# RT58X register map
Series: ARMv8-M Mainline; File version: 1.0
CPU: CM3 r0p0, little endian, MPU, no FPU, VTOR, 3 interrupt priority bits
Registers are 32-bit, read-write, reset 0x0 unless marked. A register's access mark holds for its fields unless they carry their own. Offsets are from the block's base; [hi:lo] are bit positions; {n}, {i} and the like mark numbered series.

## SYS_CTRL — SYS_CTRL Register block
Base 0x40800000
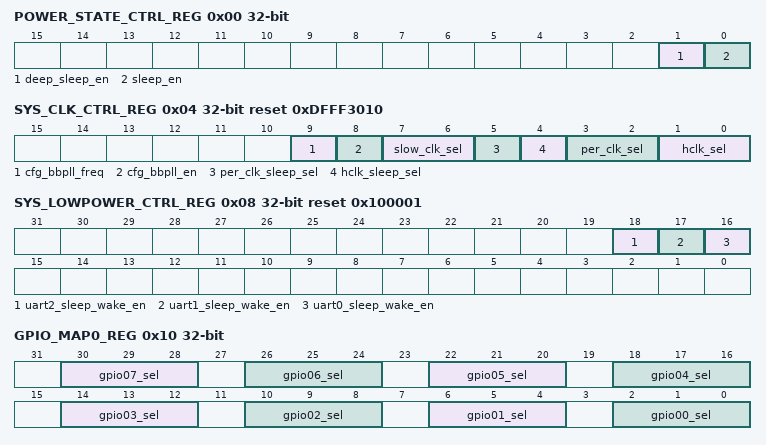
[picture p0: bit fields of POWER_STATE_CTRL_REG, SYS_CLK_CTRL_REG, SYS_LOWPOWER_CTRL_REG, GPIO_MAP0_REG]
0x00 POWER_STATE_CTRL_REG wo — power state ctrl
  [1] deep_sleep_en — Write 1 to enter DeepSleep.
    0=B_1 (Write 1 to enter DeepSleep.)
  [0] sleep_en — Write 1 to enter Sleep.
    0=B_0 (Write 1 to enter Sleep.)
0x04 SYS_CLK_CTRL_REG reset 0xDFFF3010 — sys clk ctrl
  [9] cfg_bbpll_freq — Baseband PLL frequency 0: 48MHz 1: 64MHz
    0=B_9_ITEM0 (48MHz); 1=B_9_ITEM1 (64MHz)
  [8] cfg_bbpll_en — Baseband PLL enable 0: disabl 1: enable
    0=B_8_ITEM0 (disabl); 1=B_8_ITEM1 (enable)
  [7:6] slow_clk_sel — Slow clock selection 0: From internal RCO 1: From GPIO 2: From 32M / 1000 3: From XO 32K
    0=B_6_to_7_ITEM0 (From internal RCO); 1=B_6_to_7_ITEM1 (From GPIO); 2=B_6_to_7_ITEM2 (From 32M / 1000); 3=B_6_to_7_ITEM3 (From XO 32K)
  [5] per_clk_sleep_sel — Peripheral clock selection in Sleep 0: Peripheral clock is disabled in Sleep 1: Peripheral clock is forced to 32K in Sleep.
    0=B_5_ITEM0 (Peripheral clock is disabled in Sleep); 1=B_5_ITEM1 (Peripheral clock is forced to 32K in Sleep.)
  [4] hclk_sleep_sel — HCLK sleep selection in Sleep 0: HCLK is disabled in Sleep 1: HCLK is forced to 32K in Sleep.
    0=B_4_ITEM0 (HCLK is disabled in Sleep); 1=B_4_ITEM1 (HCLK is forced to 32K in Sleep.)
  [3:2] per_clk_sel — Peripheral clock selection 0: XTAL (32M) 1: XTAL / 2 (16M) 2: Slow clock 3: Slow clock
    0=B_2_to_3_ITEM0 (XTAL (32M)); 1=B_2_to_3_ITEM1 (XTAL / 2 (16M)); 2=B_2_to_3_ITEM2 (Slow clock); 3=B_2_to_3_ITEM3 (Slow clock)
  [1:0] hclk_sel — HCLK selection 0: XTAL (32M) 1: XTAL / 2 (16M) 2: Slow clock 3: PLL clock
    0=B_0_to_1_ITEM0 (XTAL (32M)); 1=B_0_to_1_ITEM1 (XTAL / 2 (16M)); 2=B_0_to_1_ITEM2 (Slow clock); 3=B_0_to_1_ITEM3 (PLL clock)
0x08 SYS_LOWPOWER_CTRL_REG reset 0x100001 — sys lowpower ctrl
  [18] uart2_sleep_wake_en — UART2 sleep wake enable 0: disable 1: enable
    0=B_18_ITEM0 (disable); 1=B_18_ITEM1 (enable)
  [17] uart1_sleep_wake_en — UART1 sleep wake enable 0: disable 1: enable
    0=B_17_ITEM0 (disable); 1=B_17_ITEM1 (enable)
  [16] uart0_sleep_wake_en — UART0 sleep wake enable 0: disable 1: enable
    0=B_16_ITEM0 (disable); 1=B_16_ITEM1 (enable)
0x10 GPIO_MAP0_REG — gpio map0
  [30:28] gpio07_sel — 0: GPIO7 1: SPI0_CSN0 2: N/A 3: X51_TDI 4: N/A 5: EXT32K 6: UART2_RX 7: DBG_OUT[7]
    0=B_28_to_30_ITEM0 (GPIO7); 1=B_28_to_30_ITEM1 (SPI0_CSN0); 2=B_28_to_30_ITEM2 (N/A); 3=B_28_to_30_ITEM3 (X51_TDI); 4=B_28_to_30_ITEM4 (N/A); 5=B_28_to_30_ITEM5 (EXT32K); 6=B_28_to_30_ITEM6 (UART2_RX); 7=B_28_to_30_ITEM7 (DBG_OUT[7])
  [26:24] gpio06_sel — 0: GPIO6 1: SPI0_SCLK 2: N/A 3: X51_TCK 4: N/A 5: EXT32K 6: UART2_TX 7: DBG_OUT[6]
    0=B_24_to_26_ITEM0 (GPIO6); 1=B_24_to_26_ITEM1 (SPI0_SCLK); 2=B_24_to_26_ITEM2 (N/A); 3=B_24_to_26_ITEM3 (X51_TCK); 4=B_24_to_26_ITEM4 (N/A); 5=B_24_to_26_ITEM5 (EXT32K); 6=B_24_to_26_ITEM6 (UART2_TX); 7=B_24_to_26_ITEM7 (DBG_OUT[6])
  [22:20] gpio05_sel — 0: GPIO5 1: SPI0_SDATA3 2: N/A 3: X51_TMS 4: I2S0_MCLK 5: EXT32K 6: UART1_RX 7: DBG_OUT[5]
    0=B_20_to_22_ITEM0 (GPIO5); 1=B_20_to_22_ITEM1 (SPI0_SDATA3); 2=B_20_to_22_ITEM2 (N/A); 3=B_20_to_22_ITEM3 (X51_TMS); 4=B_20_to_22_ITEM4 (I2S0_MCLK); 5=B_20_to_22_ITEM5 (EXT32K); 6=B_20_to_22_ITEM6 (UART1_RX); 7=B_20_to_22_ITEM7 (DBG_OUT[5])
  [18:16] gpio04_sel — 0: GPIO4 1: SPI0_SDATA2 2: N/A 3: N/A 4: I2S0_MCLK 5: EXT32K 6: UART1_TX 7: DBG_OUT[4]
    0=B_16_to_18_ITEM0 (GPIO4); 1=B_16_to_18_ITEM1 (SPI0_SDATA2); 2=B_16_to_18_ITEM2 (N/A); 3=B_16_to_18_ITEM3 (N/A); 4=B_16_to_18_ITEM4 (I2S0_MCLK); 5=B_16_to_18_ITEM5 (EXT32K); 6=B_16_to_18_ITEM6 (UART1_TX); 7=B_16_to_18_ITEM7 (DBG_OUT[4])
  [14:12] gpio03_sel — 0: GPIO3 1: N/A 2: SPI0_CSN1 3: SPI0_CSN2 4: I2S0_SDI 5: EXT32K 6: SPI0_CSN3 7: DBG_OUT[3]
    0=B_12_to_14_ITEM0 (GPIO3); 1=B_12_to_14_ITEM1 (N/A); 2=B_12_to_14_ITEM2 (SPI0_CSN1); 3=B_12_to_14_ITEM3 (SPI0_CSN2); 4=B_12_to_14_ITEM4 (I2S0_SDI); 5=B_12_to_14_ITEM5 (EXT32K); 6=B_12_to_14_ITEM6 (SPI0_CSN3); 7=B_12_to_14_ITEM7 (DBG_OUT[3])
  [10:8] gpio02_sel — 0: GPIO2 1: N/A 2: SPI0_CSN1 3: SPI0_CSN2 4: I2S0_SDO 5: EXT32K 6: SPI0_CSN3 7: DBG_OUT[2]
    0=B_8_to_10_ITEM0 (GPIO2); 1=B_8_to_10_ITEM1 (N/A); 2=B_8_to_10_ITEM2 (SPI0_CSN1); 3=B_8_to_10_ITEM3 (SPI0_CSN2); 4=B_8_to_10_ITEM4 (I2S0_SDO); 5=B_8_to_10_ITEM5 (EXT32K); 6=B_8_to_10_ITEM6 (SPI0_CSN3); 7=B_8_to_10_ITEM7 (DBG_OUT[2])
  [6:4] gpio01_sel — 0: GPIO1 1: N/A 2: SPI0_CSN1 3: SPI0_CSN2 4: I2S0_WCK 5: EXT32K 6: SPI0_CSN3 7: DBG_OUT[1]
    0=B_4_to_6_ITEM0 (GPIO1); 1=B_4_to_6_ITEM1 (N/A); 2=B_4_to_6_ITEM2 (SPI0_CSN1); 3=B_4_to_6_ITEM3 (SPI0_CSN2); 4=B_4_to_6_ITEM4 (I2S0_WCK); 5=B_4_to_6_ITEM5 (EXT32K); 6=B_4_to_6_ITEM6 (SPI0_CSN3); 7=B_4_to_6_ITEM7 (DBG_OUT[1])
  [2:0] gpio00_sel — 0: GPIO0 1: N/A 2: SPI0_CSN1 3: SPI0_CSN2 4: I2S0_BCK 5: EXT32K 6: SPI0_CSN3 7: DBG_OUT[0]
    0=B_0_to_2_ITEM0 (GPIO0); 1=B_0_to_2_ITEM1 (N/A); 2=B_0_to_2_ITEM2 (SPI0_CSN1); 3=B_0_to_2_ITEM3 (SPI0_CSN2); 4=B_0_to_2_ITEM4 (I2S0_BCK); 5=B_0_to_2_ITEM5 (EXT32K); 6=B_0_to_2_ITEM6 (SPI0_CSN3); 7=B_0_to_2_ITEM7 (DBG_OUT[0])
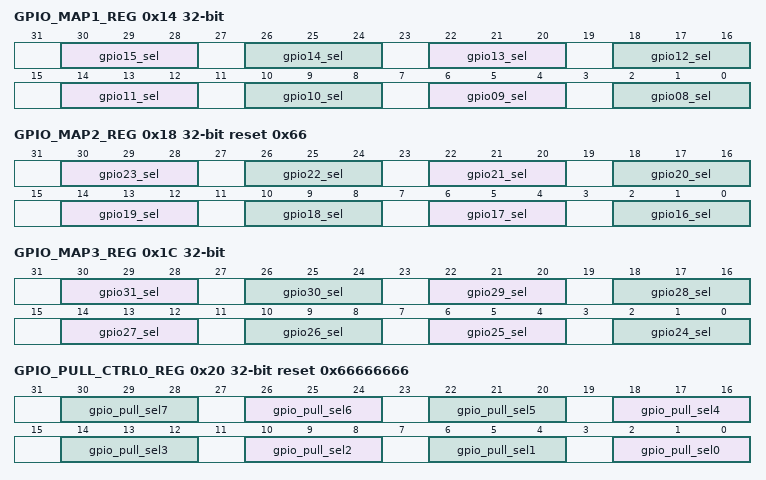
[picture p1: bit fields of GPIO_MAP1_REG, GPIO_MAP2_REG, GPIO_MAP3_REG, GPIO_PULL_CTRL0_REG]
0x14 GPIO_MAP1_REG — gpio map1
  [30:28] gpio15_sel — 0: GPIO15 1: SPI0_SDATA3 2: N/A 3: N/A 4: PWM3 5: SPI1_SDATA3 6: UART1_CTSN 7: DBG_OUT[11]
    0=B_28_to_30_ITEM0 (GPIO15); 1=B_28_to_30_ITEM1 (SPI0_SDATA3); 2=B_28_to_30_ITEM2 (N/A); 3=B_28_to_30_ITEM3 (N/A); 4=B_28_to_30_ITEM4 (PWM3); 5=B_28_to_30_ITEM5 (SPI1_SDATA3); 6=B_28_to_30_ITEM6 (UART1_CTSN); 7=B_28_to_30_ITEM7 (DBG_OUT[11])
  [26:24] gpio14_sel — 0: GPIO14 1: SPI0_SDATA2 2: N/A 3: N/A 4: PWM2 5: SPI1_SDATA2 6: UART1_RTSN 7: DBG_OUT[10]
    0=B_24_to_26_ITEM0 (GPIO14); 1=B_24_to_26_ITEM1 (SPI0_SDATA2); 2=B_24_to_26_ITEM2 (N/A); 3=B_24_to_26_ITEM3 (N/A); 4=B_24_to_26_ITEM4 (PWM2); 5=B_24_to_26_ITEM5 (SPI1_SDATA2); 6=B_24_to_26_ITEM6 (UART1_RTSN); 7=B_24_to_26_ITEM7 (DBG_OUT[10])
  [22:20] gpio13_sel — 0: GPIO13 1: PWM0 2: PWM1 3: PWM2 4: I2S0_SDI 5: PWM3 6: UART2_RX 7: PWM4
    0=B_20_to_22_ITEM0 (GPIO13); 1=B_20_to_22_ITEM1 (PWM0); 2=B_20_to_22_ITEM2 (PWM1); 3=B_20_to_22_ITEM3 (PWM2); 4=B_20_to_22_ITEM4 (I2S0_SDI); 5=B_20_to_22_ITEM5 (PWM3); 6=B_20_to_22_ITEM6 (UART2_RX); 7=B_20_to_22_ITEM7 (PWM4)
  [18:16] gpio12_sel — 0: GPIO12 1: PWM0 2: PWM1 3: PWM2 4: I2S0_SDO 5: PWM3 6: UART2_TX 7: PWM4
    0=B_16_to_18_ITEM0 (GPIO12); 1=B_16_to_18_ITEM1 (PWM0); 2=B_16_to_18_ITEM2 (PWM1); 3=B_16_to_18_ITEM3 (PWM2); 4=B_16_to_18_ITEM4 (I2S0_SDO); 5=B_16_to_18_ITEM5 (PWM3); 6=B_16_to_18_ITEM6 (UART2_TX); 7=B_16_to_18_ITEM7 (PWM4)
  [14:12] gpio11_sel — 0: GPIO11 1: PWM0 2: PWM1 3: PWM2 4: I2S0_WCK 5: PWM3 6: UART1_RX 7: PWM4
    0=B_12_to_14_ITEM0 (GPIO11); 1=B_12_to_14_ITEM1 (PWM0); 2=B_12_to_14_ITEM2 (PWM1); 3=B_12_to_14_ITEM3 (PWM2); 4=B_12_to_14_ITEM4 (I2S0_WCK); 5=B_12_to_14_ITEM5 (PWM3); 6=B_12_to_14_ITEM6 (UART1_RX); 7=B_12_to_14_ITEM7 (PWM4)
  [10:8] gpio10_sel — 0: GPIO10 1: PWM0 2: PWM1 3: PWM2 4: I2S0_BCK 5: PWM3 6: UART1_TX 7: PWM4
    0=B_8_to_10_ITEM0 (GPIO10); 1=B_8_to_10_ITEM1 (PWM0); 2=B_8_to_10_ITEM2 (PWM1); 3=B_8_to_10_ITEM3 (PWM2); 4=B_8_to_10_ITEM4 (I2S0_BCK); 5=B_8_to_10_ITEM5 (PWM3); 6=B_8_to_10_ITEM6 (UART1_TX); 7=B_8_to_10_ITEM7 (PWM4)
  [6:4] gpio09_sel — 0: GPIO9 1: SPI0_SDATA1 2: N/A 3: X51_RTCK 4: PWM1 5: EXT32K 6: N/A 7: DBG_OUT[9]
    0=B_4_to_6_ITEM0 (GPIO9); 1=B_4_to_6_ITEM1 (SPI0_SDATA1); 2=B_4_to_6_ITEM2 (N/A); 3=B_4_to_6_ITEM3 (X51_RTCK); 4=B_4_to_6_ITEM4 (PWM1); 5=B_4_to_6_ITEM5 (EXT32K); 6=B_4_to_6_ITEM6 (N/A); 7=B_4_to_6_ITEM7 (DBG_OUT[9])
  [2:0] gpio08_sel — 0: GPIO8 1: SPI0_SDATA0 2: N/A 3: X51_TDO 4: PWM0 5: N/A 6: EXT32K 7: DBG_OUT[8]
    0=B_0_to_2_ITEM0 (GPIO8); 1=B_0_to_2_ITEM1 (SPI0_SDATA0); 2=B_0_to_2_ITEM2 (N/A); 3=B_0_to_2_ITEM3 (X51_TDO); 4=B_0_to_2_ITEM4 (PWM0); 5=B_0_to_2_ITEM5 (N/A); 6=B_0_to_2_ITEM6 (EXT32K); 7=B_0_to_2_ITEM7 (DBG_OUT[8])
0x18 GPIO_MAP2_REG reset 0x66 — gpio map2
  [30:28] gpio23_sel — 0: GPIO23 1: PWM0 2: PWM1 3: PWM2 4: I2C_SDA 5: PWM3 6: N/A 7: PWM4
    0=B_28_to_30_ITEM0 (GPIO23); 1=B_28_to_30_ITEM1 (PWM0); 2=B_28_to_30_ITEM2 (PWM1); 3=B_28_to_30_ITEM3 (PWM2); 4=B_28_to_30_ITEM4 (I2C_SDA); 5=B_28_to_30_ITEM5 (PWM3); 6=B_28_to_30_ITEM6 (N/A); 7=B_28_to_30_ITEM7 (PWM4)
  [26:24] gpio22_sel — 0: GPIO22 1: PWM0 2: PWM1 3: PWM2 4: I2C_SCL 5: PWM3 6: N/A 7: PWM4
    0=B_24_to_26_ITEM0 (GPIO22); 1=B_24_to_26_ITEM1 (PWM0); 2=B_24_to_26_ITEM2 (PWM1); 3=B_24_to_26_ITEM3 (PWM2); 4=B_24_to_26_ITEM4 (I2C_SCL); 5=B_24_to_26_ITEM5 (PWM3); 6=B_24_to_26_ITEM6 (N/A); 7=B_24_to_26_ITEM7 (PWM4)
  [22:20] gpio21_sel — 0: GPIO21 1: PWM0 2: PWM1 3: PWM2 4: I2C_SDA 5: PWM3 6: UART1_CTSN 7: PWM4
    0=B_20_to_22_ITEM0 (GPIO21); 1=B_20_to_22_ITEM1 (PWM0); 2=B_20_to_22_ITEM2 (PWM1); 3=B_20_to_22_ITEM3 (PWM2); 4=B_20_to_22_ITEM4 (I2C_SDA); 5=B_20_to_22_ITEM5 (PWM3); 6=B_20_to_22_ITEM6 (UART1_CTSN); 7=B_20_to_22_ITEM7 (PWM4)
  [18:16] gpio20_sel — 0: GPIO20 1: PWM0 2: PWM1 3: PWM2 4: I2C_SCL 5: PWM3 6: UART1_RTSN 7: PWM4
    0=B_16_to_18_ITEM0 (GPIO20); 1=B_16_to_18_ITEM1 (PWM0); 2=B_16_to_18_ITEM2 (PWM1); 3=B_16_to_18_ITEM3 (PWM2); 4=B_16_to_18_ITEM4 (I2C_SCL); 5=B_16_to_18_ITEM5 (PWM3); 6=B_16_to_18_ITEM6 (UART1_RTSN); 7=B_16_to_18_ITEM7 (PWM4)
  [14:12] gpio19_sel — 0: GPIO19 1: PWM0 2: PWM1 3: PWM2 4: I2C_SDA 5: PWM3 6: UART1_CTSN 7: PWM4
    0=B_12_to_14_ITEM0 (GPIO19); 1=B_12_to_14_ITEM1 (PWM0); 2=B_12_to_14_ITEM2 (PWM1); 3=B_12_to_14_ITEM3 (PWM2); 4=B_12_to_14_ITEM4 (I2C_SDA); 5=B_12_to_14_ITEM5 (PWM3); 6=B_12_to_14_ITEM6 (UART1_CTSN); 7=B_12_to_14_ITEM7 (PWM4)
  [10:8] gpio18_sel — 0: GPIO18 1: PWM0 2: PWM1 3: PWM2 4: I2C_SCL 5: PWM3 6: UART1_RTSN 7: PWM4
    0=B_8_to_10_ITEM0 (GPIO18); 1=B_8_to_10_ITEM1 (PWM0); 2=B_8_to_10_ITEM2 (PWM1); 3=B_8_to_10_ITEM3 (PWM2); 4=B_8_to_10_ITEM4 (I2C_SCL); 5=B_8_to_10_ITEM5 (PWM3); 6=B_8_to_10_ITEM6 (UART1_RTSN); 7=B_8_to_10_ITEM7 (PWM4)
  [6:4] gpio17_sel — 0: GPIO17 1: N/A 2: N/A 3: N/A 4: N/A 5: N/A 6: UART0_TX 7: N/A
    0=B_4_to_6_ITEM0 (GPIO17); {v}=B_4_to_6_ITEM{v} (N/A) (v=1..5); 6=B_4_to_6_ITEM6 (UART0_TX); 7=B_4_to_6_ITEM7 (N/A)
  [2:0] gpio16_sel — 0: GPIO16 1: N/A 2: N/A 3: N/A 4: N/A 5: N/A 6: UART0_RX 7: N/A
    0=B_0_to_2_ITEM0 (GPIO16); {v}=B_0_to_2_ITEM{v} (N/A) (v=1..5); 6=B_0_to_2_ITEM6 (UART0_RX); 7=B_0_to_2_ITEM7 (N/A)
0x1C GPIO_MAP3_REG — gpio map3
  [30:28] gpio31_sel — 0: GPIO31 1: SPI0_SDATA1 2: N/A 3: N/A 4: N/A 5: SPI1_SDATA1 6: UART2_RX 7: DBG_OUT[15]
    0=B_28_to_30_ITEM0 (GPIO31); 1=B_28_to_30_ITEM1 (SPI0_SDATA1); 2=B_28_to_30_ITEM2 (N/A); 3=B_28_to_30_ITEM3 (N/A); 4=B_28_to_30_ITEM4 (N/A); 5=B_28_to_30_ITEM5 (SPI1_SDATA1); 6=B_28_to_30_ITEM6 (UART2_RX); 7=B_28_to_30_ITEM7 (DBG_OUT[15])
  [26:24] gpio30_sel — 0: GPIO30 1: SPI0_SDATA0 2: N/A 3: N/A 4: N/A 5: SPI1_SDATA0 6: UART2_TX 7: DBG_OUT[13]
    0=B_24_to_26_ITEM0 (GPIO30); 1=B_24_to_26_ITEM1 (SPI0_SDATA0); 2=B_24_to_26_ITEM2 (N/A); 3=B_24_to_26_ITEM3 (N/A); 4=B_24_to_26_ITEM4 (N/A); 5=B_24_to_26_ITEM5 (SPI1_SDATA0); 6=B_24_to_26_ITEM6 (UART2_TX); 7=B_24_to_26_ITEM7 (DBG_OUT[13])
  [22:20] gpio29_sel — 0: GPIO29 1: SPI0_CSN0 2: N/A 3: N/A 4: N/A 5: SPI1_CSN 6: UART1_RX 7: DBG_OUT[13]
    0=B_20_to_22_ITEM0 (GPIO29); 1=B_20_to_22_ITEM1 (SPI0_CSN0); 2=B_20_to_22_ITEM2 (N/A); 3=B_20_to_22_ITEM3 (N/A); 4=B_20_to_22_ITEM4 (N/A); 5=B_20_to_22_ITEM5 (SPI1_CSN); 6=B_20_to_22_ITEM6 (UART1_RX); 7=B_20_to_22_ITEM7 (DBG_OUT[13])
  [18:16] gpio28_sel — 0: GPIO28 1: SPI0_SCLK 2: N/A 3: N/A 4: N/A 5: SPI1_SCLK 6: UART1_TX 7: DBG_OUT[12]
    0=B_16_to_18_ITEM0 (GPIO28); 1=B_16_to_18_ITEM1 (SPI0_SCLK); 2=B_16_to_18_ITEM2 (N/A); 3=B_16_to_18_ITEM3 (N/A); 4=B_16_to_18_ITEM4 (N/A); 5=B_16_to_18_ITEM5 (SPI1_SCLK); 6=B_16_to_18_ITEM6 (UART1_TX); 7=B_16_to_18_ITEM7 (DBG_OUT[12])
  [14:12] gpio27_sel — 0: GPIO27 1: SPI0_SDATA1 2: SPI0_CSN1 3: SPI0_CSN2 4: N/A 5: SPI1_SDATA1 6: SPI0_CSN3 7: N/A
    0=B_12_to_14_ITEM0 (GPIO27); 1=B_12_to_14_ITEM1 (SPI0_SDATA1); 2=B_12_to_14_ITEM2 (SPI0_CSN1); 3=B_12_to_14_ITEM3 (SPI0_CSN2); 4=B_12_to_14_ITEM4 (N/A); 5=B_12_to_14_ITEM5 (SPI1_SDATA1); 6=B_12_to_14_ITEM6 (SPI0_CSN3); 7=B_12_to_14_ITEM7 (N/A)
  [10:8] gpio26_sel — 0: GPIO26 1: SPI0_SDATA0 2: SPI0_CSN1 3: SPI0_CSN2 4: N/A 5: SPI1_SDATA0 6: SPI0_CSN3 7: N/A
    0=B_8_to_10_ITEM0 (GPIO26); 1=B_8_to_10_ITEM1 (SPI0_SDATA0); 2=B_8_to_10_ITEM2 (SPI0_CSN1); 3=B_8_to_10_ITEM3 (SPI0_CSN2); 4=B_8_to_10_ITEM4 (N/A); 5=B_8_to_10_ITEM5 (SPI1_SDATA0); 6=B_8_to_10_ITEM6 (SPI0_CSN3); 7=B_8_to_10_ITEM7 (N/A)
  [6:4] gpio25_sel — 0: GPIO25 1: SPI0_CSN0 2: SPI0_CSN1 3: SPI0_CSN2 4: N/A 5: SPI1_CSN 6: SPI0_CSN3 7: N/A
    0=B_4_to_6_ITEM0 (GPIO25); 1=B_4_to_6_ITEM1 (SPI0_CSN0); 2=B_4_to_6_ITEM2 (SPI0_CSN1); 3=B_4_to_6_ITEM3 (SPI0_CSN2); 4=B_4_to_6_ITEM4 (N/A); 5=B_4_to_6_ITEM5 (SPI1_CSN); 6=B_4_to_6_ITEM6 (SPI0_CSN3); 7=B_4_to_6_ITEM7 (N/A)
  [2:0] gpio24_sel — 0: GPIO24 1: SPI0_SCLK 2: SPI0_CSN1 3: SPI0_CSN2 4: N/A 5: SPI1_SCLK 6: SPI0_CSN3 7: N/A
    0=B_0_to_2_ITEM0 (GPIO24); 1=B_0_to_2_ITEM1 (SPI0_SCLK); 2=B_0_to_2_ITEM2 (SPI0_CSN1); 3=B_0_to_2_ITEM3 (SPI0_CSN2); 4=B_0_to_2_ITEM4 (N/A); 5=B_0_to_2_ITEM5 (SPI1_SCLK); 6=B_0_to_2_ITEM6 (SPI0_CSN3); 7=B_0_to_2_ITEM7 (N/A)
0x20 GPIO_PULL_CTRL0_REG reset 0x66666666 — gpio pull ctrl0
  [4n+2:4n] gpio_pull_sel{n} (n=0..7) — GPIO{n} pull select 0: no pull 1: 10K pull down 2: 100K pull down 3: 1M pull down 4: no pull 5: 10k pull up 6: 100K pull up 7: 1M pull up
    0=B_{4n}_to_{4n+2}_ITEM0 (no pull); 1=B_{4n}_to_{4n+2}_ITEM1 (10K pull down); 2=B_{4n}_to_{4n+2}_ITEM2 (100K pull down); 3=B_{4n}_to_{4n+2}_ITEM3 (1M pull down); 4=B_{4n}_to_{4n+2}_ITEM4 (no pull); 5=B_{4n}_to_{4n+2}_ITEM5 (10k pull up); 6=B_{4n}_to_{4n+2}_ITEM6 (100K pull up); 7=B_{4n}_to_{4n+2}_ITEM7 (1M pull up)
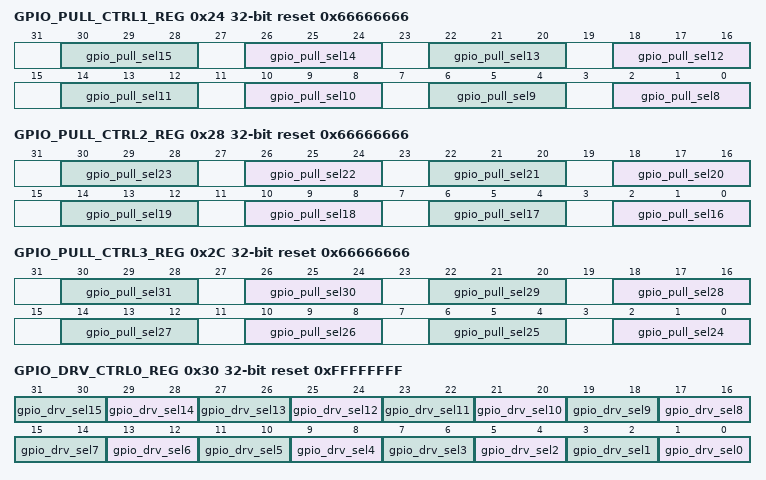
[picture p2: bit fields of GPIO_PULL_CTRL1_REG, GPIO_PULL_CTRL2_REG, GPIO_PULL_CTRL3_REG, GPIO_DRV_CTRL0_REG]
0x24 GPIO_PULL_CTRL1_REG reset 0x66666666 — gpio pull ctrl1
  [4n-30:4n-32] gpio_pull_sel{n} (n=8..15) — GPIO{n} pull select 0: no pull 1: 10K pull down 2: 100K pull down 3: 1M pull down 4: no pull 5: 10k pull up 6: 100K pull up 7: 1M pull up
    0=B_{4n-32}_to_{4n-30}_ITEM0 (no pull); 1=B_{4n-32}_to_{4n-30}_ITEM1 (10K pull down); 2=B_{4n-32}_to_{4n-30}_ITEM2 (100K pull down); 3=B_{4n-32}_to_{4n-30}_ITEM3 (1M pull down); 4=B_{4n-32}_to_{4n-30}_ITEM4 (no pull); 5=B_{4n-32}_to_{4n-30}_ITEM5 (10k pull up); 6=B_{4n-32}_to_{4n-30}_ITEM6 (100K pull up); 7=B_{4n-32}_to_{4n-30}_ITEM7 (1M pull up)
0x28 GPIO_PULL_CTRL2_REG reset 0x66666666 — gpio pull ctrl2
  [4n-62:4n-64] gpio_pull_sel{n} (n=16..23) — GPIO{n} pull select 0: no pull 1: 10K pull down 2: 100K pull down 3: 1M pull down 4: no pull 5: 10k pull up 6: 100K pull up 7: 1M pull up
    0=B_{4n-64}_to_{4n-62}_ITEM0 (no pull); 1=B_{4n-64}_to_{4n-62}_ITEM1 (10K pull down); 2=B_{4n-64}_to_{4n-62}_ITEM2 (100K pull down); 3=B_{4n-64}_to_{4n-62}_ITEM3 (1M pull down); 4=B_{4n-64}_to_{4n-62}_ITEM4 (no pull); 5=B_{4n-64}_to_{4n-62}_ITEM5 (10k pull up); 6=B_{4n-64}_to_{4n-62}_ITEM6 (100K pull up); 7=B_{4n-64}_to_{4n-62}_ITEM7 (1M pull up)
0x2C GPIO_PULL_CTRL3_REG reset 0x66666666 — gpio pull ctrl3
  [4n-94:4n-96] gpio_pull_sel{n} (n=24..31) — GPIO{n} pull select 0: no pull 1: 10K pull down 2: 100K pull down 3: 1M pull down 4: no pull 5: 10k pull up 6: 100K pull up 7: 1M pull up
    0=B_{4n-96}_to_{4n-94}_ITEM0 (no pull); 1=B_{4n-96}_to_{4n-94}_ITEM1 (10K pull down); 2=B_{4n-96}_to_{4n-94}_ITEM2 (100K pull down); 3=B_{4n-96}_to_{4n-94}_ITEM3 (1M pull down); 4=B_{4n-96}_to_{4n-94}_ITEM4 (no pull); 5=B_{4n-96}_to_{4n-94}_ITEM5 (10k pull up); 6=B_{4n-96}_to_{4n-94}_ITEM6 (100K pull up); 7=B_{4n-96}_to_{4n-94}_ITEM7 (1M pull up)
0x30 GPIO_DRV_CTRL0_REG reset 0xFFFFFFFF — gpio drv ctrl0
  [2n+1:2n] gpio_drv_sel{n} (n=0..15) — GPIO{n} driving selection 0: driving strength 0 (weakest) 1: driving strength 1 2: driving strength 2 3: driving strength 3 (strongest)
    0=B_{2n}_to_{2n+1}_ITEM0 (driving strength 0 (weakest)); 1=B_{2n}_to_{2n+1}_ITEM1 (driving strength 1); 2=B_{2n}_to_{2n+1}_ITEM2 (driving strength 2); 3=B_{2n}_to_{2n+1}_ITEM3 (driving strength 3 (strongest))
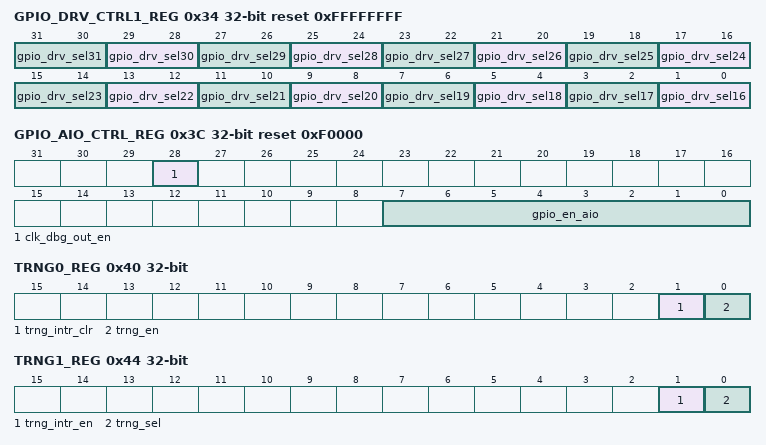
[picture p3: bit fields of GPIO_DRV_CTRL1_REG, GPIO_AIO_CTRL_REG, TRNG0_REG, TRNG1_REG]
0x34 GPIO_DRV_CTRL1_REG reset 0xFFFFFFFF — gpio drv ctrl1
  [2n-31:2n-32] gpio_drv_sel{n} (n=16..31) — GPIO{n} driving selection 0: driving strength 0 (weakest) 1: driving strength 1 2: driving strength 2 3: driving strength 3 (strongest)
    0=B_{2n-32}_to_{2n-31}_ITEM0 (driving strength 0 (weakest)); 1=B_{2n-32}_to_{2n-31}_ITEM1 (driving strength 1); 2=B_{2n-32}_to_{2n-31}_ITEM2 (driving strength 2); 3=B_{2n-32}_to_{2n-31}_ITEM3 (driving strength 3 (strongest))
0x38 GPIO_OD_CTRL_REG — GPIOx open-drain enable 0: disabled 1: enabled
0x3C GPIO_AIO_CTRL_REG reset 0xF0000 — gpio aio ctrl
  [28] clk_dbg_out_en
    0=B_28 (clk dbg out en)
  [7:0] gpio_en_aio — AIOx enable 0: disabled 1: enabled
    0=B_0_to_7 (AIOx enable 0: disabled 1: enabled)
0x40 TRNG0_REG wo — trng0
  [1] trng_intr_clr — Write 1 to clear TRNG interrupt status.
    0=B_1 (Write 1 to clear TRNG interrupt status.)
  [0] trng_en — Write 1 to trigger TRNG
    0=B_0 (Write 1 to trigger TRNG)
0x44 TRNG1_REG — trng1
  [1] trng_intr_en — TRNG interrupt enable 0: disabled 1: enabled
    0=B_1_ITEM0 (disabled); 1=B_1_ITEM1 (enabled)
  [0] trng_sel — TRNG corrector method 0: von Neumann corrector 1: XOR corrector
    0=B_0_ITEM0 (von Neumann corrector); 1=B_0_ITEM1 (XOR corrector)
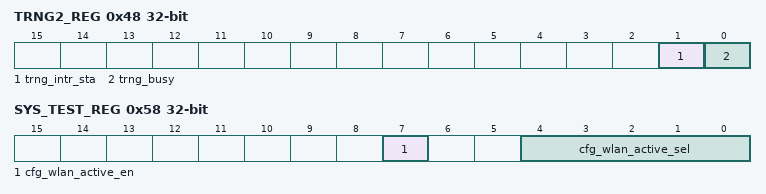
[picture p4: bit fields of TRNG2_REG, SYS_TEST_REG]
0x48 TRNG2_REG ro — trng2
  [1] trng_intr_sta — TRNG interrupt status 0: no interrupt pending 1: interrupt pending
    0=B_1_ITEM0 (no interrupt pending); 1=B_1_ITEM1 (interrupt pending)
  [0] trng_busy — TRNG busy 0: not busy 1: busy
    0=B_0_ITEM0 (not busy); 1=B_0_ITEM1 (busy)
0x4C TRNG3_REG ro — TRNG output
0x58 SYS_TEST_REG — sys test
  [7] cfg_wlan_active_en — Enable GPIOxx input for wlan_active for RT569 PTA function.
    0=B_7 (Enable GPIOxx input for wlan_active for RT569 PTA function.)
  [4:0] cfg_wlan_active_sel — Select the related GPIOxx input for wlan_active for RT569 PTA function.
    0=B_0_to_4 (Select the related GPIOxx input for wlan_active for RT569 PTA function.)
{0x60+4i} SYS_SCRATCHPAD_{i}_REG (i=0..5) — Scratch PAD{i}. This value is kept after waking up from Deep Sleep.
0x78 SYS_SCRATCHPAD_6_REG — Scratch PAD6. Reserved for System Use. [0] : Enable resetting CM3 peripherals when WatchDog reset is triggered. [1] : Enable resetting ApbGPIO and Remap when WatchDog reset is triggered. [2] : Enable resetting RT569 when WatchDog reset is triggered. Others: N/A
0x7C SYS_SCRATCHPAD_7_REG — Scratch PAD7. This value is kept after waking up from Deep Sleep. [8] : Disable ICE. Once this bit is set to 1, it can't be set to 0 again except power-on reset or external reset. 0: Enable ICE (default) 1: Disable ICE [15:9] Don't USE due to no function. Others : They can be written normally.
0x80 DEEPSLEEP_WAKEUP_REG — Set the corresponding bits to enable the wakeup of GPIOx in Deep Sleep
0x84 DEEPSLEEP_INV_REG — Set the corresponding bits to invert the GPIOx for wakeup in Deep Sleep
0x90 RT570_CHIP_INFO_REG ro reset 0x7702F — rt570 chip info
  [7:4] rt570_chip_rev — Chip Revision
    0=B_4_to_7 (Chip Revision)
